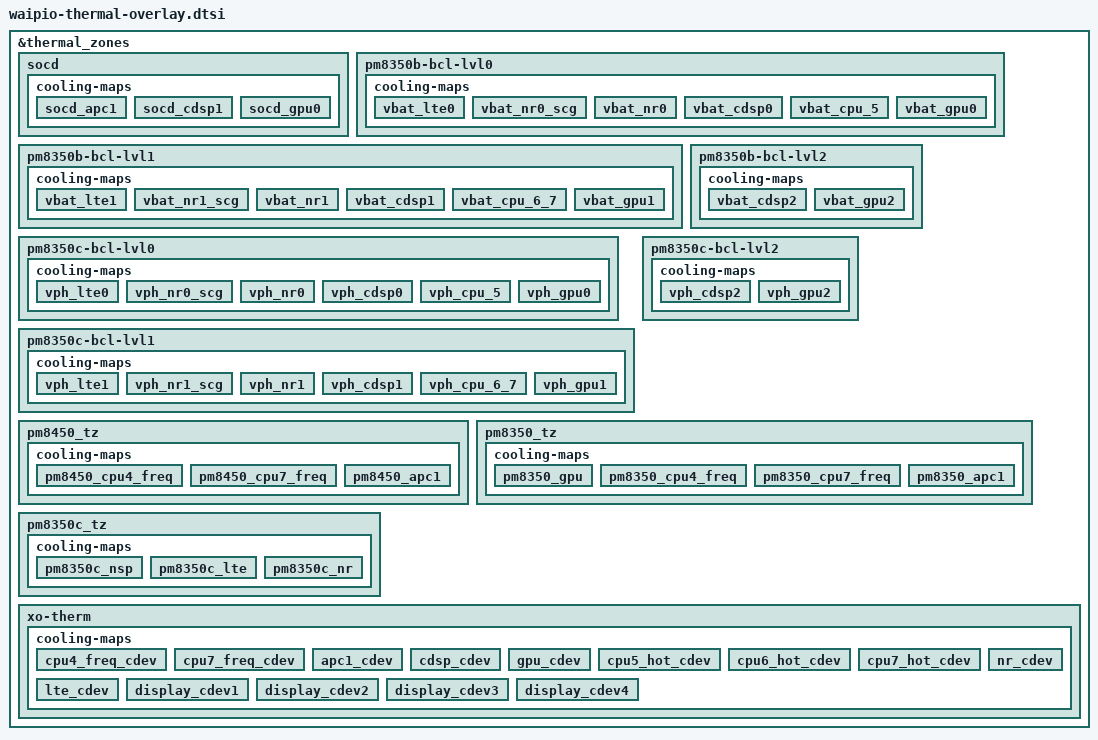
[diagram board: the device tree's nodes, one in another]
#include <dt-bindings/thermal/thermal_qti.h>

&thermal_zones {
	socd {
		cooling-maps {
			socd_apc1 {
				trip = <&socd_trip>;
				cooling-device = <&APC1_pause 1 1>;
			};

			socd_cdsp1 {
				trip = <&socd_trip>;
				cooling-device = <&cdsp_sw 4 4>;
			};

			socd_gpu0 {
				trip = <&socd_trip>;
				cooling-device = <&msm_gpu 4 4>;
			};
		};
	};

	pm8350b-bcl-lvl0 {
		cooling-maps {
			vbat_lte0 {
				trip = <&b_bcl_lvl0>;
				cooling-device = <&modem_lte_dsc 8 8>;
			};

			vbat_nr0_scg {
				trip = <&b_bcl_lvl0>;
				cooling-device = <&modem_nr_scg_dsc 3 3>;
			};

			vbat_nr0 {
				trip = <&b_bcl_lvl0>;
				cooling-device = <&modem_nr_dsc 6 6>;
			};

			vbat_cdsp0 {
				trip = <&b_bcl_lvl0>;
				cooling-device = <&cdsp_sw 2 2>;
			};

			vbat_cpu_5 {
				trip = <&b_bcl_lvl0>;
				cooling-device = <&cpu5_pause 1 1>;
			};

			vbat_gpu0 {
				trip = <&b_bcl_lvl0>;
				cooling-device = <&msm_gpu 2 2>;
			};
		};
	};

	pm8350b-bcl-lvl1 {
		cooling-maps {
			vbat_lte1 {
				trip = <&b_bcl_lvl1>;
				cooling-device = <&modem_lte_dsc 10 10>;
			};

			vbat_nr1_scg {
				trip = <&b_bcl_lvl1>;
				cooling-device = <&modem_nr_scg_dsc 10 10>;
			};

			vbat_nr1 {
				trip = <&b_bcl_lvl1>;
				cooling-device = <&modem_nr_dsc 9 9>;
			};

			vbat_cdsp1 {
				trip = <&b_bcl_lvl1>;
				cooling-device = <&cdsp_sw 4 4>;
			};

			vbat_cpu_6_7 {
				trip = <&b_bcl_lvl1>;
				cooling-device = <&cpu_6_7_pause 1 1>;
			};

			vbat_gpu1 {
				trip = <&b_bcl_lvl1>;
				cooling-device = <&msm_gpu 4 4>;
			};
		};
	};

	pm8350b-bcl-lvl2 {
		cooling-maps {
			vbat_cdsp2 {
				trip = <&b_bcl_lvl2>;
				cooling-device = <&cdsp_sw 5 THERMAL_NO_LIMIT>;
			};

			vbat_gpu2 {
				trip = <&b_bcl_lvl2>;
				cooling-device = <&msm_gpu 7 THERMAL_NO_LIMIT>;
			};
		};
	};

	pm8350c-bcl-lvl0 {
		cooling-maps {
			vph_lte0 {
				trip = <&c_bcl_lvl0>;
				cooling-device = <&modem_lte_dsc 8 8>;
			};

			vph_nr0_scg {
				trip = <&c_bcl_lvl0>;
				cooling-device = <&modem_nr_scg_dsc 3 3>;
			};

			vph_nr0 {
				trip = <&c_bcl_lvl0>;
				cooling-device = <&modem_nr_dsc 6 6>;
			};

			vph_cdsp0 {
				trip = <&c_bcl_lvl0>;
				cooling-device = <&cdsp_sw 2 2>;
			};

			vph_cpu_5 {
				trip = <&c_bcl_lvl0>;
				cooling-device = <&cpu5_pause 1 1>;
			};

			vph_gpu0 {
				trip = <&c_bcl_lvl0>;
				cooling-device = <&msm_gpu 2 2>;
			};
		};
	};

	pm8350c-bcl-lvl1 {
		cooling-maps {
			vph_lte1 {
				trip = <&c_bcl_lvl1>;
				cooling-device = <&modem_lte_dsc 10 10>;
			};

			vph_nr1_scg {
				trip = <&c_bcl_lvl1>;
				cooling-device = <&modem_nr_scg_dsc 10 10>;
			};

			vph_nr1 {
				trip = <&c_bcl_lvl1>;
				cooling-device = <&modem_nr_dsc 9 9>;
			};

			vph_cdsp1 {
				trip = <&c_bcl_lvl1>;
				cooling-device = <&cdsp_sw 4 4>;
			};

			vph_cpu_6_7 {
				trip = <&c_bcl_lvl1>;
				cooling-device = <&cpu_6_7_pause 1 1>;
			};

			vph_gpu1 {
				trip = <&c_bcl_lvl1>;
				cooling-device = <&msm_gpu 4 4>;
			};
		};
	};

	pm8350c-bcl-lvl2 {
		cooling-maps {
			vph_cdsp2 {
				trip = <&c_bcl_lvl2>;
				cooling-device = <&cdsp_sw 5 THERMAL_NO_LIMIT>;
			};

			vph_gpu2 {
				trip = <&c_bcl_lvl2>;
				cooling-device = <&msm_gpu 7 THERMAL_NO_LIMIT>;
			};
		};
	};

	pm8450_tz {
		cooling-maps {
			pm8450_cpu4_freq {
				trip = <&pm8450_trip0>;
				cooling-device = <&CPU4 15 THERMAL_NO_LIMIT>;
			};

			pm8450_cpu7_freq {
				trip = <&pm8450_trip0>;
				cooling-device = <&CPU7 15 THERMAL_NO_LIMIT>;
			};

			pm8450_apc1 {
				trip = <&pm8450_trip0>;
				cooling-device = <&APC1_pause 1 1>;
			};
		};
	};

	pm8350_tz {
		cooling-maps {
			pm8350_gpu {
				trip = <&pm8350_trip0>;
				cooling-device = <&msm_gpu 7 THERMAL_NO_LIMIT>;
			};

			pm8350_cpu4_freq {
				trip = <&pm8350_trip0>;
				cooling-device = <&CPU4 15 THERMAL_NO_LIMIT>;
			};

			pm8350_cpu7_freq {
				trip = <&pm8350_trip0>;
				cooling-device = <&CPU7 15 THERMAL_NO_LIMIT>;
			};

			pm8350_apc1 {
				trip = <&pm8350_trip0>;
				cooling-device = <&APC1_pause 1 1>;
			};
		};
	};

	pm8350c_tz {
		cooling-maps {
			pm8350c_nsp {
				trip = <&pm8350c_trip0>;
				cooling-device = <&cdsp_sw 5 THERMAL_NO_LIMIT>;
			};

			pm8350c_lte {
				trip = <&pm8350c_trip0>;
				cooling-device = <&modem_lte_dsc 255 255>;
			};

			pm8350c_nr {
				trip = <&pm8350c_trip0>;
				cooling-device = <&modem_nr_scg_dsc 255 255>;
			};
		};
	};

	xo-therm {
		cooling-maps {
			cpu4_freq_cdev {
				trip = <&xo_config0>;
				cooling-device = <&CPU4 15 THERMAL_NO_LIMIT>;
			};

			cpu7_freq_cdev {
				trip = <&xo_config0>;
				cooling-device = <&CPU7 15 THERMAL_NO_LIMIT>;
			};

			apc1_cdev {
				trip = <&xo_config0>;
				cooling-device = <&APC1_pause 1 1>;
			};

			cdsp_cdev {
				trip = <&xo_config0>;
				cooling-device = <&cdsp_sw 5 THERMAL_NO_LIMIT>;
			};

			gpu_cdev {
				trip = <&xo_config0>;
				cooling-device = <&msm_gpu 7 THERMAL_NO_LIMIT>;
			};

			cpu5_hot_cdev {
				trip = <&xo_config1>;
				cooling-device = <&cpu5_hotplug 1 1>;
			};

			cpu6_hot_cdev {
				trip = <&xo_config1>;
				cooling-device = <&cpu6_hotplug 1 1>;
			};

			cpu7_hot_cdev {
				trip = <&xo_config1>;
				cooling-device = <&cpu7_hotplug 1 1>;
			};

			lte_cdev {
				trip = <&xo_config1>;
				cooling-device = <&modem_lte_dsc 255 255>;
			};

			nr_cdev {
				trip = <&xo_config1>;
				cooling-device = <&modem_nr_scg_dsc 255 255>;
			};

			display_cdev1 {
				trip = <&display_test_config1>;
				cooling-device = <&display_fps 1 1>;
			};

			display_cdev2 {
				trip = <&display_test_config2>;
				cooling-device = <&display_fps 2 2>;
			};

			display_cdev3 {
				trip = <&display_test_config3>;
				cooling-device = <&display_fps 3 3>;
			};

			display_cdev4 {
				trip = <&display_test_config4>;
				cooling-device = <&display_fps 4 4>;
			};
		};
	};
};
